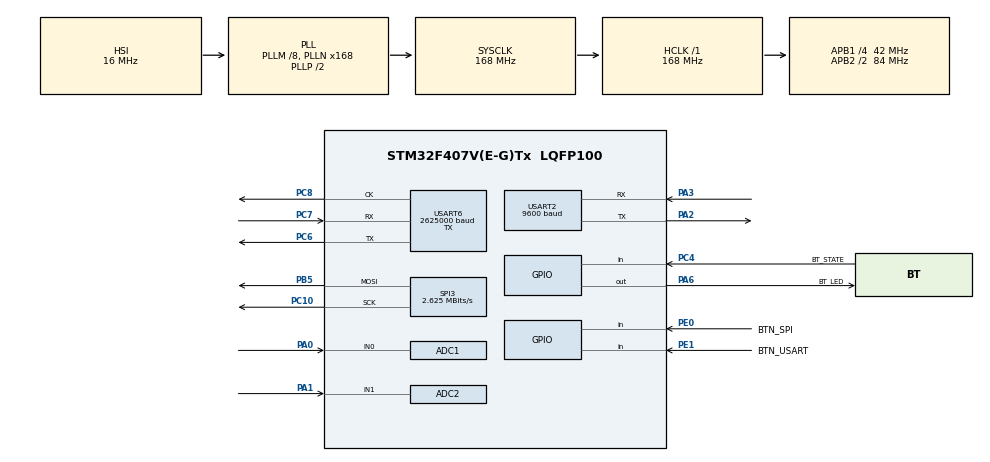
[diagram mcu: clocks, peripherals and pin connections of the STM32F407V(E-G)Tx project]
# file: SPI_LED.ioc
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ADC1.Channel-0\#ChannelRegularConversion=ADC_CHANNEL_0
ADC1.ExternalTrigConv=ADC_EXTERNALTRIGCONV_T2_TRGO
ADC1.NbrOfConversionFlag=1
ADC1.Rank-0\#ChannelRegularConversion=1
ADC1.SamplingTime-0\#ChannelRegularConversion=ADC_SAMPLETIME_15CYCLES
ADC1.master=1
ADC2.Channel-0\#ChannelRegularConversion=ADC_CHANNEL_1
ADC2.ContinuousConvMode=DISABLE
ADC2.DMAContinuousRequests=ENABLE
ADC2.ExternalTrigConv=ADC_EXTERNALTRIGCONV_T3_TRGO
ADC2.NbrOfConversionFlag=1
ADC2.Rank-0\#ChannelRegularConversion=1
ADC2.SamplingTime-0\#ChannelRegularConversion=ADC_SAMPLETIME_3CYCLES
Dma.ADC1.2.Direction=DMA_PERIPH_TO_MEMORY
Dma.ADC1.2.FIFOMode=DMA_FIFOMODE_DISABLE
Dma.ADC1.2.Instance=DMA2_Stream0
Dma.ADC1.2.MemDataAlignment=DMA_MDATAALIGN_HALFWORD
Dma.ADC1.2.MemInc=DMA_MINC_ENABLE
Dma.ADC1.2.Mode=DMA_CIRCULAR
Dma.ADC1.2.PeriphDataAlignment=DMA_PDATAALIGN_HALFWORD
Dma.ADC1.2.PeriphInc=DMA_PINC_DISABLE
Dma.ADC1.2.Priority=DMA_PRIORITY_LOW
Dma.ADC2.3.Direction=DMA_PERIPH_TO_MEMORY
Dma.ADC2.3.FIFOMode=DMA_FIFOMODE_DISABLE
Dma.ADC2.3.Instance=DMA2_Stream2
Dma.ADC2.3.MemDataAlignment=DMA_MDATAALIGN_HALFWORD
Dma.ADC2.3.MemInc=DMA_MINC_ENABLE
Dma.ADC2.3.Mode=DMA_CIRCULAR
Dma.ADC2.3.PeriphDataAlignment=DMA_PDATAALIGN_HALFWORD
Dma.ADC2.3.PeriphInc=DMA_PINC_DISABLE
Dma.ADC2.3.Priority=DMA_PRIORITY_LOW
Dma.Request0=SPI3_TX
Dma.Request1=USART6_TX
Dma.Request2=ADC1
Dma.Request3=ADC2
Dma.SPI3_TX.0.Direction=DMA_MEMORY_TO_PERIPH
Dma.SPI3_TX.0.FIFOMode=DMA_FIFOMODE_DISABLE
Dma.SPI3_TX.0.Instance=DMA1_Stream5
Dma.SPI3_TX.0.MemDataAlignment=DMA_MDATAALIGN_BYTE
Dma.SPI3_TX.0.MemInc=DMA_MINC_ENABLE
Dma.SPI3_TX.0.Mode=DMA_NORMAL
Dma.SPI3_TX.0.PeriphDataAlignment=DMA_PDATAALIGN_BYTE
Dma.SPI3_TX.0.PeriphInc=DMA_PINC_DISABLE
Dma.SPI3_TX.0.Priority=DMA_PRIORITY_LOW
Dma.USART6_TX.1.Direction=DMA_MEMORY_TO_PERIPH
Dma.USART6_TX.1.FIFOMode=DMA_FIFOMODE_DISABLE
Dma.USART6_TX.1.Instance=DMA2_Stream6
Dma.USART6_TX.1.MemDataAlignment=DMA_MDATAALIGN_BYTE
Dma.USART6_TX.1.MemInc=DMA_MINC_ENABLE
Dma.USART6_TX.1.Mode=DMA_NORMAL
Dma.USART6_TX.1.PeriphDataAlignment=DMA_PDATAALIGN_BYTE
Dma.USART6_TX.1.PeriphInc=DMA_PINC_DISABLE
Dma.USART6_TX.1.Priority=DMA_PRIORITY_LOW
Mcu.Family=STM32F4
Mcu.Name=STM32F407V(E-G)Tx
Mcu.Package=LQFP100
NVIC.DMA1_Stream5_IRQn=true\:5\:0\:true\:false\:true\:false\:true\:true
NVIC.DMA2_Stream0_IRQn=true\:1\:0\:true\:false\:true\:false\:true\:true
NVIC.DMA2_Stream2_IRQn=true\:3\:0\:true\:false\:true\:false\:true\:true
NVIC.DMA2_Stream6_IRQn=true\:5\:0\:true\:false\:true\:false\:true\:true
NVIC.PriorityGroup=NVIC_PRIORITYGROUP_4
NVIC.SPI3_IRQn=true\:0\:0\:false\:false\:true\:true\:true\:true
NVIC.USART2_IRQn=true\:2\:0\:true\:false\:true\:true\:true\:true
NVIC.USART6_IRQn=true\:0\:0\:false\:false\:true\:true\:true\:true
PA0-WKUP.Signal=ADCx_IN0
PA1.Signal=ADCx_IN1
PA2.Mode=Asynchronous
PA2.Signal=USART2_TX
PA3.Mode=Asynchronous
PA3.Signal=USART2_RX
PA6.GPIO_Label=BT_LED
PA6.Signal=GPIO_Output
PB5.Mode=TX_Only_Simplex_Unidirect_Master
PB5.Signal=SPI3_MOSI
PC10.Mode=TX_Only_Simplex_Unidirect_Master
PC10.Signal=SPI3_SCK
PC4.GPIO_Label=BT_STATE
PC4.GPIO_PuPd=GPIO_PULLDOWN
PC4.Signal=GPIO_Input
PC6.Mode=Synchronous
PC6.Signal=USART6_TX
PC7.Mode=Synchronous
PC7.Signal=USART6_RX
PC8.Mode=Synchronous
PC8.Signal=USART6_CK
PE0.GPIO_Label=BTN_SPI
PE0.GPIO_PuPd=GPIO_PULLDOWN
PE0.Signal=GPIO_Input
PE1.GPIO_Label=BTN_USART
PE1.GPIO_PuPd=GPIO_PULLDOWN
PE1.Signal=GPIO_Input
ProjectManager.HeapSize=0x200
ProjectManager.StackSize=0x400
ProjectManager.TargetToolchain=STM32CubeIDE
RCC.48MHZClocksFreq_Value=84000000
RCC.AHBFreq_Value=168000000
RCC.APB1CLKDivider=RCC_HCLK_DIV4
RCC.APB1Freq_Value=42000000
RCC.APB1TimFreq_Value=84000000
RCC.APB2CLKDivider=RCC_HCLK_DIV2
RCC.APB2Freq_Value=84000000
RCC.APB2TimFreq_Value=168000000
RCC.CortexFreq_Value=168000000
RCC.HCLKFreq_Value=168000000
RCC.HSE_VALUE=25000000
RCC.HSI_VALUE=16000000
RCC.LSE_VALUE=32768
RCC.PLLM=8
RCC.PLLN=168
RCC.SYSCLKFreq_VALUE=168000000
RCC.SYSCLKSource=RCC_SYSCLKSOURCE_PLLCLK
RCC.VCOOutputFreq_Value=336000000
SH.ADCx_IN0.0=ADC1_IN0,IN0
SH.ADCx_IN1.0=ADC2_IN1,IN1
SPI3.BaudRatePrescaler=SPI_BAUDRATEPRESCALER_16
SPI3.CalculateBaudRate=2.625 MBits/s
SPI3.Direction=SPI_DIRECTION_2LINES
SPI3.Mode=SPI_MODE_MASTER
SPI3.VirtualType=VM_MASTER
STMicroelectronics.X-CUBE-ALGOBUILD.1.4.0.LibraryCcDSPOoLibraryJjDSPOoLibrary=true
TIM2.Period=1300
TIM2.TIM_MasterOutputTrigger=TIM_TRGO_UPDATE
TIM2.TIM_MasterSlaveMode=TIM_MASTERSLAVEMODE_ENABLE
TIM3.Period=499
TIM3.Prescaler=4199
TIM3.TIM_MasterOutputTrigger=TIM_TRGO_UPDATE
TIM3.TIM_MasterSlaveMode=TIM_MASTERSLAVEMODE_ENABLE
USART2.BaudRate=9600
USART2.VirtualMode=VM_ASYNC
USART2.WordLength=WORDLENGTH_8B
USART6.BaudRate=2625000
USART6.Mode=MODE_TX
USART6.VirtualMode=VM_SYNC
USART6.WordLength=WORDLENGTH_8B
VP_STMicroelectronics.X-CUBE-ALGOBUILD_VS_DSPOoLibraryJjLibrary_1.4.0_1.4.0.Mode=DSPOoLibraryJjLibrary
VP_TIM2_VS_ClockSourceINT.Mode=Internal
VP_TIM3_VS_ClockSourceINT.Mode=Internal
board=custom

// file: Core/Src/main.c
/* USER CODE BEGIN Header */
/**
  ******************************************************************************
  * @file           : main.c
  * @brief          : Main program body
  ******************************************************************************
  * @attention
  *
  * Copyright (c) 2025 STMicroelectronics.
  * All rights reserved.
  *
  * This software is licensed under terms that can be found in the LICENSE file
  * in the root directory of this software component.
  * If no LICENSE file comes with this software, it is provided AS-IS.
  *
  ******************************************************************************
  */
/* USER CODE END Header */
#include "main.h"

/* USER CODE BEGIN Includes */
#include "effect.h"
#include "bluetooth.h"

/* USER CODE END Includes */

ADC_HandleTypeDef hadc1;
ADC_HandleTypeDef hadc2;
DMA_HandleTypeDef hdma_adc1;
DMA_HandleTypeDef hdma_adc2;

SPI_HandleTypeDef hspi3;
DMA_HandleTypeDef hdma_spi3_tx;

TIM_HandleTypeDef htim2;
TIM_HandleTypeDef htim3;

UART_HandleTypeDef huart2;
USART_HandleTypeDef husart6;
DMA_HandleTypeDef hdma_usart6_tx;

/* USER CODE BEGIN PV */
extern volatile uint8_t effect_mode_spi;
extern volatile uint8_t effect_mode_uart;

/* USER CODE END PV */

void SystemClock_Config(void);
static void MX_GPIO_Init(void);
static void MX_DMA_Init(void);
static void MX_SPI3_Init(void);
static void MX_USART6_Init(void);
static void MX_ADC1_Init(void);
static void MX_TIM2_Init(void);
static void MX_USART2_UART_Init(void);
static void MX_ADC2_Init(void);
static void MX_TIM3_Init(void);

int main(void)
{

  /* MCU Configuration--------------------------------------------------------*/

  /* Reset of all peripherals, Initializes the Flash interface and the Systick. */
  HAL_Init();

  /* Configure the system clock */
  SystemClock_Config();

  /* Initialize all configured peripherals */
  MX_GPIO_Init();
  MX_DMA_Init();
  MX_SPI3_Init();
  MX_USART6_Init();
  MX_ADC1_Init();
  MX_TIM2_Init();
  MX_USART2_UART_Init();
  MX_ADC2_Init();
  MX_TIM3_Init();
  /* USER CODE BEGIN 2 */
  led_init();
  audio_init();
  bluetooth_init();
  knob_init();
  button_init();
  /* USER CODE END 2 */

  /* Infinite loop */
  /* USER CODE BEGIN WHILE */
  // Biến dùng để đếm thời gian tự chuyển hiệu ứng
  while (1)
  {
	  bluetooth_check_connection();
      led_effects_manager();
	  HAL_Delay(1);
  }
    /* USER CODE END WHILE */

}

void SystemClock_Config(void)
{
  RCC_OscInitTypeDef RCC_OscInitStruct = {0};
  RCC_ClkInitTypeDef RCC_ClkInitStruct = {0};

  /** Configure the main internal regulator output voltage
  */
  __HAL_RCC_PWR_CLK_ENABLE();
  __HAL_PWR_VOLTAGESCALING_CONFIG(PWR_REGULATOR_VOLTAGE_SCALE1);

  /** Initializes the RCC Oscillators according to the specified parameters
  * in the RCC_OscInitTypeDef structure.
  */
  RCC_OscInitStruct.OscillatorType = RCC_OSCILLATORTYPE_HSI;
  RCC_OscInitStruct.HSIState = RCC_HSI_ON;
  RCC_OscInitStruct.HSICalibrationValue = RCC_HSICALIBRATION_DEFAULT;
  RCC_OscInitStruct.PLL.PLLState = RCC_PLL_ON;
  RCC_OscInitStruct.PLL.PLLSource = RCC_PLLSOURCE_HSI;
  RCC_OscInitStruct.PLL.PLLM = 8;
  RCC_OscInitStruct.PLL.PLLN = 168;
  RCC_OscInitStruct.PLL.PLLP = RCC_PLLP_DIV2;
  RCC_OscInitStruct.PLL.PLLQ = 4;
  if (HAL_RCC_OscConfig(&RCC_OscInitStruct) != HAL_OK)
  {
    Error_Handler();
  }

  /** Initializes the CPU, AHB and APB buses clocks
  */
  RCC_ClkInitStruct.ClockType = RCC_CLOCKTYPE_HCLK|RCC_CLOCKTYPE_SYSCLK
                              |RCC_CLOCKTYPE_PCLK1|RCC_CLOCKTYPE_PCLK2;
  RCC_ClkInitStruct.SYSCLKSource = RCC_SYSCLKSOURCE_PLLCLK;
  RCC_ClkInitStruct.AHBCLKDivider = RCC_SYSCLK_DIV1;
  RCC_ClkInitStruct.APB1CLKDivider = RCC_HCLK_DIV4;
  RCC_ClkInitStruct.APB2CLKDivider = RCC_HCLK_DIV2;

  if (HAL_RCC_ClockConfig(&RCC_ClkInitStruct, FLASH_LATENCY_5) != HAL_OK)
  {
    Error_Handler();
  }
}

static void MX_ADC1_Init(void)
{

  ADC_ChannelConfTypeDef sConfig = {0};

  /** Configure the global features of the ADC (Clock, Resolution, Data Alignment and number of conversion)
  */
  hadc1.Instance = ADC1;
  hadc1.Init.ClockPrescaler = ADC_CLOCK_SYNC_PCLK_DIV4;
  hadc1.Init.Resolution = ADC_RESOLUTION_12B;
  hadc1.Init.ScanConvMode = DISABLE;
  hadc1.Init.ContinuousConvMode = DISABLE;
  hadc1.Init.DiscontinuousConvMode = DISABLE;
  hadc1.Init.ExternalTrigConvEdge = ADC_EXTERNALTRIGCONVEDGE_RISING;
  hadc1.Init.ExternalTrigConv = ADC_EXTERNALTRIGCONV_T2_TRGO;
  hadc1.Init.DataAlign = ADC_DATAALIGN_RIGHT;
  hadc1.Init.NbrOfConversion = 1;
  hadc1.Init.DMAContinuousRequests = DISABLE;
  hadc1.Init.EOCSelection = ADC_EOC_SINGLE_CONV;
  if (HAL_ADC_Init(&hadc1) != HAL_OK)
  {
    Error_Handler();
  }

  /** Configure for the selected ADC regular channel its corresponding rank in the sequencer and its sample time.
  */
  sConfig.Channel = ADC_CHANNEL_0;
  sConfig.Rank = 1;
  sConfig.SamplingTime = ADC_SAMPLETIME_15CYCLES;
  if (HAL_ADC_ConfigChannel(&hadc1, &sConfig) != HAL_OK)
  {
    Error_Handler();
  }

}

static void MX_ADC2_Init(void)
{

  ADC_ChannelConfTypeDef sConfig = {0};

  /** Configure the global features of the ADC (Clock, Resolution, Data Alignment and number of conversion)
  */
  hadc2.Instance = ADC2;
  hadc2.Init.ClockPrescaler = ADC_CLOCK_SYNC_PCLK_DIV4;
  hadc2.Init.Resolution = ADC_RESOLUTION_12B;
  hadc2.Init.ScanConvMode = DISABLE;
  hadc2.Init.ContinuousConvMode = DISABLE;
  hadc2.Init.DiscontinuousConvMode = DISABLE;
  hadc2.Init.ExternalTrigConvEdge = ADC_EXTERNALTRIGCONVEDGE_RISING;
  hadc2.Init.ExternalTrigConv = ADC_EXTERNALTRIGCONV_T3_TRGO;
  hadc2.Init.DataAlign = ADC_DATAALIGN_RIGHT;
  hadc2.Init.NbrOfConversion = 1;
  hadc2.Init.DMAContinuousRequests = ENABLE;
  hadc2.Init.EOCSelection = ADC_EOC_SINGLE_CONV;
  if (HAL_ADC_Init(&hadc2) != HAL_OK)
  {
    Error_Handler();
  }

  /** Configure for the selected ADC regular channel its corresponding rank in the sequencer and its sample time.
  */
  sConfig.Channel = ADC_CHANNEL_1;
  sConfig.Rank = 1;
  sConfig.SamplingTime = ADC_SAMPLETIME_3CYCLES;
  if (HAL_ADC_ConfigChannel(&hadc2, &sConfig) != HAL_OK)
  {
    Error_Handler();
  }

}

static void MX_SPI3_Init(void)
{

  /* SPI3 parameter configuration*/
  hspi3.Instance = SPI3;
  hspi3.Init.Mode = SPI_MODE_MASTER;
  hspi3.Init.Direction = SPI_DIRECTION_2LINES;
  hspi3.Init.DataSize = SPI_DATASIZE_8BIT;
  hspi3.Init.CLKPolarity = SPI_POLARITY_LOW;
  hspi3.Init.CLKPhase = SPI_PHASE_1EDGE;
  hspi3.Init.NSS = SPI_NSS_SOFT;
  hspi3.Init.BaudRatePrescaler = SPI_BAUDRATEPRESCALER_16;
  hspi3.Init.FirstBit = SPI_FIRSTBIT_MSB;
  hspi3.Init.TIMode = SPI_TIMODE_DISABLE;
  hspi3.Init.CRCCalculation = SPI_CRCCALCULATION_DISABLE;
  hspi3.Init.CRCPolynomial = 10;
  if (HAL_SPI_Init(&hspi3) != HAL_OK)
  {
    Error_Handler();
  }

}

static void MX_TIM2_Init(void)
{

  TIM_ClockConfigTypeDef sClockSourceConfig = {0};
  TIM_MasterConfigTypeDef sMasterConfig = {0};

  htim2.Instance = TIM2;
  htim2.Init.Prescaler = 0;
  htim2.Init.CounterMode = TIM_COUNTERMODE_UP;
  htim2.Init.Period = 1300;
  htim2.Init.ClockDivision = TIM_CLOCKDIVISION_DIV1;
  htim2.Init.AutoReloadPreload = TIM_AUTORELOAD_PRELOAD_DISABLE;
  if (HAL_TIM_Base_Init(&htim2) != HAL_OK)
  {
    Error_Handler();
  }
  sClockSourceConfig.ClockSource = TIM_CLOCKSOURCE_INTERNAL;
  if (HAL_TIM_ConfigClockSource(&htim2, &sClockSourceConfig) != HAL_OK)
  {
    Error_Handler();
  }
  sMasterConfig.MasterOutputTrigger = TIM_TRGO_UPDATE;
  sMasterConfig.MasterSlaveMode = TIM_MASTERSLAVEMODE_ENABLE;
  if (HAL_TIMEx_MasterConfigSynchronization(&htim2, &sMasterConfig) != HAL_OK)
  {
    Error_Handler();
  }

}

static void MX_TIM3_Init(void)
{

  TIM_ClockConfigTypeDef sClockSourceConfig = {0};
  TIM_MasterConfigTypeDef sMasterConfig = {0};

  htim3.Instance = TIM3;
  htim3.Init.Prescaler = 4199;
  htim3.Init.CounterMode = TIM_COUNTERMODE_UP;
  htim3.Init.Period = 499;
  htim3.Init.ClockDivision = TIM_CLOCKDIVISION_DIV1;
  htim3.Init.AutoReloadPreload = TIM_AUTORELOAD_PRELOAD_DISABLE;
  if (HAL_TIM_Base_Init(&htim3) != HAL_OK)
  {
    Error_Handler();
  }
  sClockSourceConfig.ClockSource = TIM_CLOCKSOURCE_INTERNAL;
  if (HAL_TIM_ConfigClockSource(&htim3, &sClockSourceConfig) != HAL_OK)
  {
    Error_Handler();
  }
  sMasterConfig.MasterOutputTrigger = TIM_TRGO_UPDATE;
  sMasterConfig.MasterSlaveMode = TIM_MASTERSLAVEMODE_ENABLE;
  if (HAL_TIMEx_MasterConfigSynchronization(&htim3, &sMasterConfig) != HAL_OK)
  {
    Error_Handler();
  }

}

static void MX_USART2_UART_Init(void)
{

  huart2.Instance = USART2;
  huart2.Init.BaudRate = 9600;
  huart2.Init.WordLength = UART_WORDLENGTH_8B;
  huart2.Init.StopBits = UART_STOPBITS_1;
  huart2.Init.Parity = UART_PARITY_NONE;
  huart2.Init.Mode = UART_MODE_TX_RX;
  huart2.Init.HwFlowCtl = UART_HWCONTROL_NONE;
  huart2.Init.OverSampling = UART_OVERSAMPLING_16;
  if (HAL_UART_Init(&huart2) != HAL_OK)
  {
    Error_Handler();
  }

}

static void MX_USART6_Init(void)
{

  husart6.Instance = USART6;
  husart6.Init.BaudRate = 2625000;
  husart6.Init.WordLength = USART_WORDLENGTH_8B;
  husart6.Init.StopBits = USART_STOPBITS_1;
  husart6.Init.Parity = USART_PARITY_NONE;
  husart6.Init.Mode = USART_MODE_TX;
  husart6.Init.CLKPolarity = USART_POLARITY_LOW;
  husart6.Init.CLKPhase = USART_PHASE_1EDGE;
  husart6.Init.CLKLastBit = USART_LASTBIT_DISABLE;
  if (HAL_USART_Init(&husart6) != HAL_OK)
  {
    Error_Handler();
  }

}

static void MX_DMA_Init(void)
{

  /* DMA controller clock enable */
  __HAL_RCC_DMA1_CLK_ENABLE();
  __HAL_RCC_DMA2_CLK_ENABLE();

  /* DMA interrupt init */
  /* DMA1_Stream5_IRQn interrupt configuration */
  HAL_NVIC_SetPriority(DMA1_Stream5_IRQn, 5, 0);
  HAL_NVIC_EnableIRQ(DMA1_Stream5_IRQn);
  /* DMA2_Stream0_IRQn interrupt configuration */
  HAL_NVIC_SetPriority(DMA2_Stream0_IRQn, 1, 0);
  HAL_NVIC_EnableIRQ(DMA2_Stream0_IRQn);
  /* DMA2_Stream2_IRQn interrupt configuration */
  HAL_NVIC_SetPriority(DMA2_Stream2_IRQn, 3, 0);
  HAL_NVIC_EnableIRQ(DMA2_Stream2_IRQn);
  /* DMA2_Stream6_IRQn interrupt configuration */
  HAL_NVIC_SetPriority(DMA2_Stream6_IRQn, 5, 0);
  HAL_NVIC_EnableIRQ(DMA2_Stream6_IRQn);

}

static void MX_GPIO_Init(void)
{
  GPIO_InitTypeDef GPIO_InitStruct = {0};

  /* GPIO Ports Clock Enable */
  __HAL_RCC_GPIOA_CLK_ENABLE();
  __HAL_RCC_GPIOC_CLK_ENABLE();
  __HAL_RCC_GPIOB_CLK_ENABLE();
  __HAL_RCC_GPIOE_CLK_ENABLE();

  /*Configure GPIO pin Output Level */
  HAL_GPIO_WritePin(BT_LED_GPIO_Port, BT_LED_Pin, GPIO_PIN_RESET);

  /*Configure GPIO pin : BT_LED_Pin */
  GPIO_InitStruct.Pin = BT_LED_Pin;
  GPIO_InitStruct.Mode = GPIO_MODE_OUTPUT_PP;
  GPIO_InitStruct.Pull = GPIO_NOPULL;
  GPIO_InitStruct.Speed = GPIO_SPEED_FREQ_LOW;
  HAL_GPIO_Init(BT_LED_GPIO_Port, &GPIO_InitStruct);

  /*Configure GPIO pin : BT_STATE_Pin */
  GPIO_InitStruct.Pin = BT_STATE_Pin;
  GPIO_InitStruct.Mode = GPIO_MODE_INPUT;
  GPIO_InitStruct.Pull = GPIO_PULLDOWN;
  HAL_GPIO_Init(BT_STATE_GPIO_Port, &GPIO_InitStruct);

  /*Configure GPIO pins : BTN_SPI_Pin BTN_USART_Pin */
  GPIO_InitStruct.Pin = BTN_SPI_Pin|BTN_USART_Pin;
  GPIO_InitStruct.Mode = GPIO_MODE_INPUT;
  GPIO_InitStruct.Pull = GPIO_PULLDOWN;
  HAL_GPIO_Init(GPIOE, &GPIO_InitStruct);

}

/* USER CODE BEGIN 4 */
void HAL_SPI_TxCpltCallback(SPI_HandleTypeDef *hspi)
{
    // This is where you would set a flag, e.g.
    // g_transfer_complete = 1;
    // Your main loop can then check this flag before
    // filling the buffer with new data and calling show_leds() again.
}
/* USER CODE END 4 */

void Error_Handler(void)
{
  __disable_irq();
  while (1)
  {
  }
}
